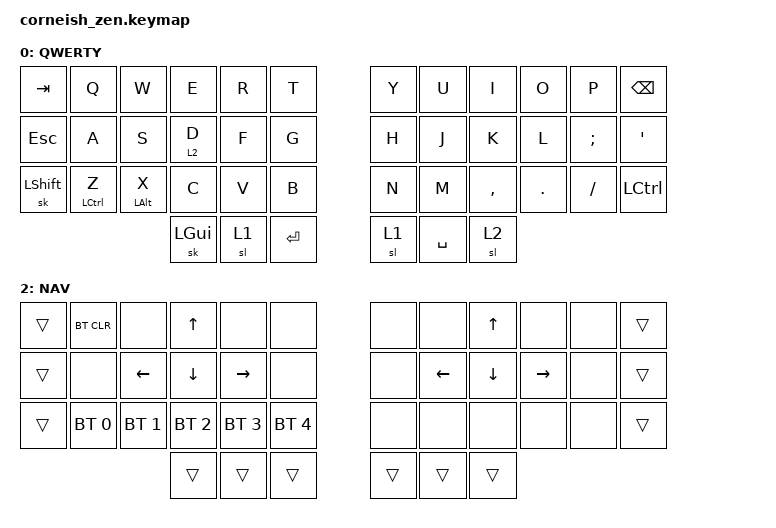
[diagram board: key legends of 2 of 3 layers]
#include <behaviors.dtsi>
#include <dt-bindings/zmk/keys.h>
#include <dt-bindings/zmk/bt.h>
#include <dt-bindings/zmk/outputs.h>

/ {
  chosen {
    zmk,matrix_transform = &default_transform;
    //zmk,matrix_transform = &five_column_transform;
  };
};

/ {
    combos {
        compatible = "zmk,combos";
        combo_del {
            timeout-ms = <50>;
            key-positions = <11 12>;
            bindings = <&kp DEL>;
        };
    };
};

/ {
        keymap {
                compatible = "zmk,keymap";

                default_layer {
                        label = "QWERTY";
// --------------------------------------------------------------------------------------------------------------------------------------
// |  TAB   |     Q     |      W     |      E      |  R  |   T   |=====|  Y  |   U   |     I     |    O    |   P   |   BKSP   |
// |  ESC   |     A     |      S     |      D      |  F  |   G   |=====|  H  |   J   |     K     |    L    |   ;   |    '     |
// |  SHFT  |   CTRL/Z  |   ALT/X    |      C      |  V  |   B   |=====|  N  |   M   |     ,     |    .    |   /   |   LCTRL  |
//                                   | GUI | Lower | ENTER |   | Lower | SPACE  | Raise |
                        bindings = <
   &kp TAB   &kp Q        &kp W        &kp E        &kp R   &kp T       &kp Y  &kp U  &kp I       &kp O     &kp P     &kp BSPC
   &kp ESC   &kp A        &kp S        &lt 2 D      &kp F   &kp G       &kp H  &kp J  &kp K       &kp L     &kp SEMI  &kp SQT
   &sk LSHFT &mt LCTRL Z  &mt LALT X   &kp C        &kp V   &kp B       &kp N  &kp M  &kp COMMA   &kp DOT   &kp FSLH  &kp LCTRL
                                          &sk LGUI &sl 1 &kp RET   &sl 1 &kp SPACE &sl 2
                        >;
                };
                lower_layer {
                        label = "NUMBER";
// --------------------------------------------------------------------------------------------------------------------------------------
// |  TAB  |    !     |    @     |    {    |    }    |     %      |==========|       &       |   1   |   2   |   3   |   =   |  BKSP  |
// | ESC   |    $     |    #     |    (    |    )    |    `       |==========|       *       |   4   |   5   |   6   |   -   |   +     |
// | SHFT  |          |    ~     |    [    |    ]    |    \       |==========|       0       |   7   |   8   |   9   |   _   |        |
//                    | GUI |     | SPC |   | ENT |     | ALT |
                        bindings = <
   &kp TAB    &kp EXCL   &kp AT     &kp LBRC    &kp RBRC   &kp PRCNT           &kp AMPS        &kp N1   &kp N2  &kp N3   &kp EQUAL   &kp BSPC
   &kp ESC    &kp DLLR   &kp HASH   &kp LPAR    &kp RPAR   &kp GRAVE           &kp KP_MULTIPLY &kp N4   &kp N5  &kp N6   &kp MINUS   &kp PLUS
   &kp LSHFT  &trans     &kp TILDE  &kp LBKT    &kp RBKT   &kp BSLH            &kp N0          &kp N7   &kp N8  &kp N9   &kp UNDER
                          	        &trans &trans &trans              &trans &trans &trans
                        >;
                };

                raise_layer {
                        label = "NAV";
// ---------------------------------------------------------------------------------------------------------------------------------------
// | TAB   | BTCLR    |             |     UP    |               |       |====|        |           |    UP    |         |        |  BKSP |
// | CTRL  |          |     LEFT    |     DN    |   RIGHT       |       |====|        |   LEFT    |    DN    |  RIGHT  |        |       |
// | SHFT  |  BT1     |     BT2     |    BT3    |    BT4        |  BT5  |====|        |           |          |         |        | 
//                    | GUI  |     | SPC |    | ENT |     | ALT |
                        bindings = <
   &trans &bt BT_CLR   &none         &kp UP         &none         &none         &none     &none      &kp UP    &none        &none  &trans  
   &trans &none        &kp LEFT      &kp DOWN       &kp RIGHT     &none         &none     &kp LEFT   &kp DOWN  &kp RIGHT    &none  &trans  
   &trans &bt BT_SEL 0 &bt BT_SEL 1  &bt BT_SEL 2   &bt BT_SEL 3  &bt BT_SEL 4  &none     &none      &none     &none        &none  &trans
                    	            &trans &trans &trans                             &trans &trans &trans
                        >;
                };
        };
};

